# RN8XXX_V2 register map
File version: 1.0
Registers are 32-bit, read-write, reset 0x0 unless marked. A register's access mark holds for its fields unless they carry their own. Offsets are from the block's base; [hi:lo] are bit positions.

## SPI0 — synchronous peripheral interface
Base 0x40020000
Same registers: SPI1 0x40050000, SPI2 0x40054000, SPI3 0x40058000
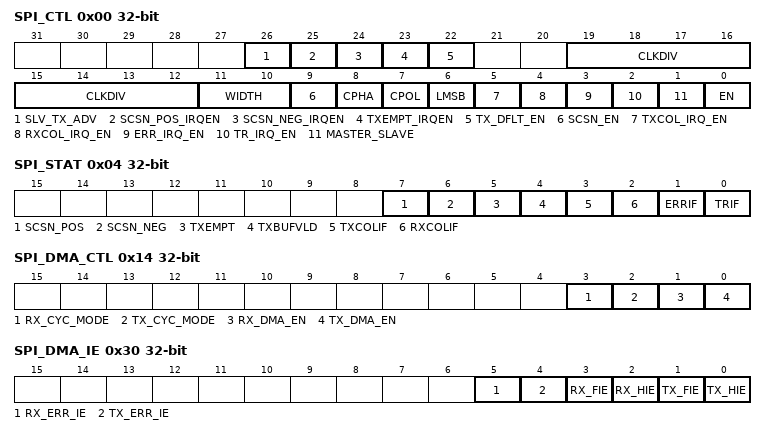
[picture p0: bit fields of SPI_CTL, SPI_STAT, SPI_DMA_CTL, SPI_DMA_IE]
0x00 SPI_CTL — control
  [26] SLV_TX_ADV — SPI slave high speed mode enable
    0=disable; 1=enable
  [25] SCSN_POS_IRQEN — CSN POS interrupt
    0=disable (interrupt disable); 1=enable (interrupt enable)
  [24] SCSN_NEG_IRQEN — CSN NEG interrupt
    0=disable (interrupt disable); 1=enable (interrupt enable)
  [23] TXEMPT_IRQEN — transmit empty interrupt
    0=disable (transmit empty interrupt disable); 1=enable (transmit empty interrupt enable)
  [22] TX_DFLT_EN — transmit data when TX buffer empty
    0=TX_DATA (transmit the data last in SPI_TXDATA register); 1=TX_DFLT_DATA (transmit the data in SPI_TXDFLT register)
  [19:12] CLKDIV — clock divisor for SCK.frequency of SCK is (frequency of system clock)/(2*(CLKDIV+1))
  [11:10] WIDTH — data width selection
    0=d8 (frame data width is 8 bits); 1=d16 (frame data width is 16 bits); 2=d32 (frame data width is 32 bits); 3=reserved (do not use)
  [9] SCSN_EN — SCSN error detection enable.applicable in master mode
    0=disable (SCSN disabled.SCSN act as general purpose IO); 1=enable (SCSN enabled.SCSN act as part of SPI bus protocal)
  [8] CPHA — clock phase selection
    0=sample (postive edge of SCK used to sample data); 1=setup (postive edge of SCK used for data setup)
  [7] CPOL — clock polarity selection
    0=low (SCK set as low when bus idle); 1=high (SCK set as high when bus idle)
  [6] LMSB — LSB or MSB selection
    0=MSB (MSB transfer first); 1=LSB (LSB transfer first)
  [5] TXCOL_IRQ_EN — transmit data collision interrupt enable
    0=disable (do not generate interrupt on transmit data collision event); 1=enable (generate interrupt on transmit data collision event)
  [4] RXCOL_IRQ_EN — receive data collision interrupt enable
    0=disable (do not generate interrupt on receive data collision event); 1=enable (generate interrupt on receive data collision event)
  [3] ERR_IRQ_EN — SCSN error interrupt enable
    0=disable (do not generate interrupt on SCSN error event); 1=enable (generate interrupt on SCSN error event)
  [2] TR_IRQ_EN — transmit interrupt enable
    0=disable (do not generate interrupt on transmit event); 1=enable (generate interrupt on transmit event)
  [1] MASTER_SLAVE — master slave selection
    0=slave mode; 1=master mode
  [0] EN — module enable
    0=disable (transmit and receive engine disabled); 1=enable (transmit and receive engine enabled)
0x04 SPI_STAT — status
  [7] SCSN_POS — SCSN_NEG pull high(slave mode) event
    0=not_pull high (CSN pin not pull high); 1=pull high (CSN pin pull high)
  [6] SCSN_NEG — SCSN_NEG pull low(slave mode) event
    0=not_pull low (CSN pin not pull low); 1=pull low (CSN pin pull low)
  [5] TXEMPT — transmit buffer empty flag
    0=not_empty (transmit buffer not empty); 1=empty (transmit buffer empty)
  [4] TXBUFVLD — transmit busy flag
    0=not_busy (on outstanding transmit in operation); 1=busy (transmit in operation)
  [3] TXCOLIF write-1-clears — transmit collision flag
    0=no_collision (on outstanding transmit collision event); 1=collision (transmit collision event pending)
  [2] RXCOLIF write-1-clears — receive overflow flag
    0=no_overflow (on outstanding receive overflow event(no transmit data or transmit not over)); 1=overflow (receive overflow event pending)
  [1] ERRIF write-1-clears — SCSN collision flag bit
    0=no_collision (on outstanding SCSN collision event); 1=collision (SCSN collision event pending)
  [0] TRIF write-1-clears — transmit flag
    0=no_transmit (on outstanding transmit event(no transmit data or transmit not over)); 1=transmit event pending
0x08 SPI_TXDATA — transmit data
0x0C SPI_RXDATA ro — receive data
0x10 SPI_TXDFLT — tx default data
0x14 SPI_DMA_CTL — SPI DMA control register
  [all] fields
    0=disable; 1=enable
  [3] RX_CYC_MODE — RX DMA enable
  [2] TX_CYC_MODE — RX DMA enable
  [1] RX_DMA_EN — RX DMA enable
  [0] TX_DMA_EN — TX DMA enable
0x18 SPI_DMA_TBADR — SPI DMA TX base address
  [16:0] SPI_DMA_TBADR — DMA base addr
0x1C SPI_DMA_RBADR — SPI DMA RX base address
  [16:0] SPI_DMA_RBADR
0x20 SPI_DMA_TLEN — SPI DMA TX length
  [16:0] SPI_DMA_TLEN
0x24 SPI_DMA_RLEN — SPI DMA RX length
  [16:0] SPI_DMA_RLEN
0x28 SPI_DMA_TADR — SPI DMA TX current address
  [16:0] SPI_DMA_TADR
0x2C SPI_DMA_RADR — SPI DMA RX current address
  [16:0] SPI_DMA_RADR
0x30 SPI_DMA_IE — SPI DMA interrupt enable
  [all] fields
    0=disable; 1=enable
  [5] RX_ERR_IE — RX error interrupt enable
  [4] TX_ERR_IE — TX error interrupt enable
  [3] RX_FIE — RX full interrupt enable
  [2] RX_HIE — RX half-full interrupt enable
  [1] TX_FIE — TX full interrupt enable
  [0] TX_HIE — TX half-full interrupt enable
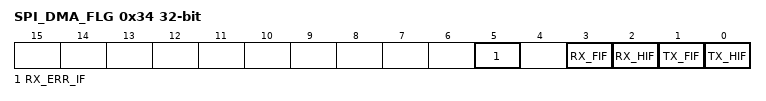
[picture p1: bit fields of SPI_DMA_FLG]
0x34 SPI_DMA_FLG — SPI DMA interrupt flag
  [all] fields
    0=no_pending (not pending); 1=pending (interrupt pending)
  [5] RX_ERR_IF write-1-clears — RX error interrupt
  [3] RX_FIF write-1-clears — RX full interrupt
  [2] RX_HIF write-1-clears — RX half-full interrupt
  [1] TX_FIF write-1-clears — TX full interrupt
  [0] TX_HIF write-1-clears — TX half-full interrupt
